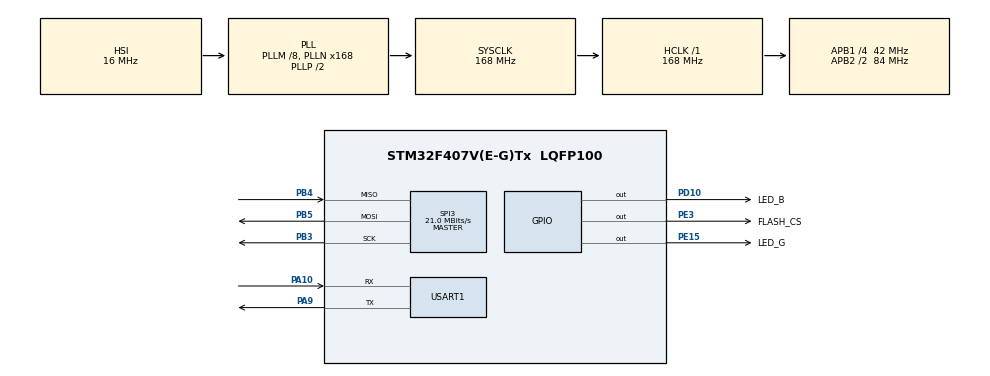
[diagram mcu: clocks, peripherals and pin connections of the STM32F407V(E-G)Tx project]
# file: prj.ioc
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Dma.Request0=SPI3_TX
Dma.Request1=SPI3_RX
Dma.SPI3_RX.1.Direction=DMA_PERIPH_TO_MEMORY
Dma.SPI3_RX.1.FIFOMode=DMA_FIFOMODE_DISABLE
Dma.SPI3_RX.1.Instance=DMA1_Stream0
Dma.SPI3_RX.1.MemDataAlignment=DMA_MDATAALIGN_BYTE
Dma.SPI3_RX.1.MemInc=DMA_MINC_ENABLE
Dma.SPI3_RX.1.Mode=DMA_NORMAL
Dma.SPI3_RX.1.PeriphDataAlignment=DMA_PDATAALIGN_BYTE
Dma.SPI3_RX.1.PeriphInc=DMA_PINC_DISABLE
Dma.SPI3_RX.1.Priority=DMA_PRIORITY_HIGH
Dma.SPI3_TX.0.Direction=DMA_MEMORY_TO_PERIPH
Dma.SPI3_TX.0.FIFOMode=DMA_FIFOMODE_DISABLE
Dma.SPI3_TX.0.Instance=DMA1_Stream5
Dma.SPI3_TX.0.MemDataAlignment=DMA_MDATAALIGN_BYTE
Dma.SPI3_TX.0.MemInc=DMA_MINC_ENABLE
Dma.SPI3_TX.0.Mode=DMA_NORMAL
Dma.SPI3_TX.0.PeriphDataAlignment=DMA_PDATAALIGN_BYTE
Dma.SPI3_TX.0.PeriphInc=DMA_PINC_DISABLE
Dma.SPI3_TX.0.Priority=DMA_PRIORITY_HIGH
FREERTOS.Tasks01=defaultTask,24,128,StartDefaultTask,Default,NULL,Dynamic,NULL,NULL;flashTask,24,512,FlashTask,Default,NULL,Static,flashTaskBuffer,flashTaskControlBlock
FREERTOS.configENABLE_FPU=1
Mcu.Family=STM32F4
Mcu.Name=STM32F407V(E-G)Tx
Mcu.Package=LQFP100
NVIC.DMA1_Stream0_IRQn=true\:0\:0\:false\:false\:true\:false\:false\:true\:true
NVIC.DMA1_Stream5_IRQn=true\:5\:0\:false\:false\:true\:true\:false\:true\:true
NVIC.PriorityGroup=NVIC_PRIORITYGROUP_4
NVIC.TIM1_UP_TIM10_IRQn=true\:15\:0\:false\:false\:true\:false\:false\:true\:true
NVIC.TimeBase=TIM1_UP_TIM10_IRQn
NVIC.TimeBaseIP=TIM1
NVIC.USART1_IRQn=true\:5\:0\:false\:false\:true\:true\:true\:true\:true
PA10.Mode=Asynchronous
PA10.Signal=USART1_RX
PA13.Mode=Serial_Wire
PA13.Signal=SYS_JTMS-SWDIO
PA14.Mode=Serial_Wire
PA14.Signal=SYS_JTCK-SWCLK
PA9.Mode=Asynchronous
PA9.Signal=USART1_TX
PB3.Mode=Full_Duplex_Master
PB3.Signal=SPI3_SCK
PB4.Mode=Full_Duplex_Master
PB4.Signal=SPI3_MISO
PB5.Mode=Full_Duplex_Master
PB5.Signal=SPI3_MOSI
PC14-OSC32_IN.Mode=LSE-External-Oscillator
PC14-OSC32_IN.Signal=RCC_OSC32_IN
PC15-OSC32_OUT.Mode=LSE-External-Oscillator
PC15-OSC32_OUT.Signal=RCC_OSC32_OUT
PD10.GPIO_Label=LED_B
PD10.Signal=GPIO_Output
PE15.GPIO_Label=LED_G
PE15.Signal=GPIO_Output
PE3.GPIO_Label=FLASH_CS
PE3.GPIO_PuPd=GPIO_PULLUP
PE3.GPIO_Speed=GPIO_SPEED_FREQ_VERY_HIGH
PE3.PinState=GPIO_PIN_SET
PE3.Signal=GPIO_Output
PH0-OSC_IN.Mode=HSE-External-Oscillator
PH0-OSC_IN.Signal=RCC_OSC_IN
PH1-OSC_OUT.Mode=HSE-External-Oscillator
PH1-OSC_OUT.Signal=RCC_OSC_OUT
ProjectManager.HeapSize=0x200
ProjectManager.StackSize=0x400
ProjectManager.TargetToolchain=MDK-ARM V5.32
RCC.48MHZClocksFreq_Value=84000000
RCC.AHBFreq_Value=168000000
RCC.APB1CLKDivider=RCC_HCLK_DIV4
RCC.APB1Freq_Value=42000000
RCC.APB1TimFreq_Value=84000000
RCC.APB2CLKDivider=RCC_HCLK_DIV2
RCC.APB2Freq_Value=84000000
RCC.APB2TimFreq_Value=168000000
RCC.CortexFreq_Value=168000000
RCC.HCLKFreq_Value=168000000
RCC.HSE_VALUE=25000000
RCC.HSI_VALUE=16000000
RCC.PLLM=8
RCC.PLLN=168
RCC.SYSCLKFreq_VALUE=168000000
RCC.SYSCLKSource=RCC_SYSCLKSOURCE_PLLCLK
RCC.VCOOutputFreq_Value=336000000
SPI3.CalculateBaudRate=21.0 MBits/s
SPI3.Direction=SPI_DIRECTION_2LINES
SPI3.Mode=SPI_MODE_MASTER
SPI3.VirtualType=VM_MASTER
USART1.VirtualMode=VM_ASYNC
VP_FREERTOS_VS_CMSIS_V2.Mode=CMSIS_V2
VP_SYS_VS_tim1.Mode=TIM1
board=custom

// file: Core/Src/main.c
/* USER CODE BEGIN Header */
/**
  ******************************************************************************
  * @file           : main.c
  * @brief          : Main program body
  ******************************************************************************
  * @attention
  *
  * Copyright (c) 2025 STMicroelectronics.
  * All rights reserved.
  *
  * This software is licensed under terms that can be found in the LICENSE file
  * in the root directory of this software component.
  * If no LICENSE file comes with this software, it is provided AS-IS.
  *
  ******************************************************************************
  */
/* USER CODE END Header */
#include "main.h"
#include "cmsis_os.h"
#include "dma.h"
#include "spi.h"
#include "usart.h"
#include "gpio.h"

void SystemClock_Config(void);
void MX_FREERTOS_Init(void);

int main(void)
{

  /* MCU Configuration--------------------------------------------------------*/

  /* Reset of all peripherals, Initializes the Flash interface and the Systick. */
  HAL_Init();

  /* Configure the system clock */
  SystemClock_Config();

  /* Initialize all configured peripherals */
  MX_GPIO_Init();
  MX_DMA_Init();
  MX_SPI3_Init();
  MX_USART1_UART_Init();

  /* Init scheduler */
  osKernelInitialize();

  /* Call init function for freertos objects (in cmsis_os2.c) */
  MX_FREERTOS_Init();

  /* Start scheduler */
  osKernelStart();

  /* We should never get here as control is now taken by the scheduler */

  /* Infinite loop */
  while (1)
  {

  }
}

void SystemClock_Config(void)
{
  RCC_OscInitTypeDef RCC_OscInitStruct = {0};
  RCC_ClkInitTypeDef RCC_ClkInitStruct = {0};

  /** Configure the main internal regulator output voltage
  */
  __HAL_RCC_PWR_CLK_ENABLE();
  __HAL_PWR_VOLTAGESCALING_CONFIG(PWR_REGULATOR_VOLTAGE_SCALE1);

  /** Initializes the RCC Oscillators according to the specified parameters
  * in the RCC_OscInitTypeDef structure.
  */
  RCC_OscInitStruct.OscillatorType = RCC_OSCILLATORTYPE_HSI;
  RCC_OscInitStruct.HSIState = RCC_HSI_ON;
  RCC_OscInitStruct.HSICalibrationValue = RCC_HSICALIBRATION_DEFAULT;
  RCC_OscInitStruct.PLL.PLLState = RCC_PLL_ON;
  RCC_OscInitStruct.PLL.PLLSource = RCC_PLLSOURCE_HSI;
  RCC_OscInitStruct.PLL.PLLM = 8;
  RCC_OscInitStruct.PLL.PLLN = 168;
  RCC_OscInitStruct.PLL.PLLP = RCC_PLLP_DIV2;
  RCC_OscInitStruct.PLL.PLLQ = 4;
  if (HAL_RCC_OscConfig(&RCC_OscInitStruct) != HAL_OK)
  {
    Error_Handler();
  }

  /** Initializes the CPU, AHB and APB buses clocks
  */
  RCC_ClkInitStruct.ClockType = RCC_CLOCKTYPE_HCLK|RCC_CLOCKTYPE_SYSCLK
                              |RCC_CLOCKTYPE_PCLK1|RCC_CLOCKTYPE_PCLK2;
  RCC_ClkInitStruct.SYSCLKSource = RCC_SYSCLKSOURCE_PLLCLK;
  RCC_ClkInitStruct.AHBCLKDivider = RCC_SYSCLK_DIV1;
  RCC_ClkInitStruct.APB1CLKDivider = RCC_HCLK_DIV4;
  RCC_ClkInitStruct.APB2CLKDivider = RCC_HCLK_DIV2;

  if (HAL_RCC_ClockConfig(&RCC_ClkInitStruct, FLASH_LATENCY_5) != HAL_OK)
  {
    Error_Handler();
  }
}

void HAL_TIM_PeriodElapsedCallback(TIM_HandleTypeDef *htim)
{
  if (htim->Instance == TIM1)
  {
    HAL_IncTick();
  }
}

void Error_Handler(void)
{
  __disable_irq();
  while (1)
  {
  }
}

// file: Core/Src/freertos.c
/* USER CODE BEGIN Header */
/**
  ******************************************************************************
  * File Name          : freertos.c
  * Description        : Code for freertos applications
  ******************************************************************************
  * @attention
  *
  * Copyright (c) 2025 STMicroelectronics.
  * All rights reserved.
  *
  * This software is licensed under terms that can be found in the LICENSE file
  * in the root directory of this software component.
  * If no LICENSE file comes with this software, it is provided AS-IS.
  *
  ******************************************************************************
  */
/* USER CODE END Header */

#include "FreeRTOS.h"
#include "task.h"
#include "main.h"
#include "cmsis_os.h"

/* USER CODE BEGIN Includes */
#include "Dev_Flash.h"
#include "usart.h"
/* USER CODE END Includes */

typedef StaticTask_t osStaticThreadDef_t;

/* Definitions for defaultTask */
osThreadId_t defaultTaskHandle;
const osThreadAttr_t defaultTask_attributes = {
  .name = "defaultTask",
  .stack_size = 128 * 4,
  .priority = (osPriority_t) osPriorityNormal,
};
/* Definitions for flashTask */
osThreadId_t flashTaskHandle;
uint32_t flashTaskBuffer[ 512 ];
osStaticThreadDef_t flashTaskControlBlock;
const osThreadAttr_t flashTask_attributes = {
  .name = "flashTask",
  .cb_mem = &flashTaskControlBlock,
  .cb_size = sizeof(flashTaskControlBlock),
  .stack_mem = &flashTaskBuffer[0],
  .stack_size = sizeof(flashTaskBuffer),
  .priority = (osPriority_t) osPriorityNormal,
};

void StartDefaultTask(void *argument);
void FlashTask(void *argument);

void MX_FREERTOS_Init(void); /* (MISRA C 2004 rule 8.1) */

void MX_FREERTOS_Init(void) {

  /* Create the thread(s) */
  /* creation of defaultTask */
  defaultTaskHandle = osThreadNew(StartDefaultTask, NULL, &defaultTask_attributes);

  /* creation of flashTask */
  flashTaskHandle = osThreadNew(FlashTask, NULL, &flashTask_attributes);

}

void StartDefaultTask(void *argument)
{
  /* USER CODE BEGIN StartDefaultTask */
  /* Infinite loop */
  for(;;)
  {
    HAL_GPIO_TogglePin(LED_G_GPIO_Port, LED_G_Pin);
    HAL_GPIO_TogglePin(LED_B_GPIO_Port, LED_B_Pin);
    osDelay(200);
  }
  /* USER CODE END StartDefaultTask */
}

void FlashTask(void *argument)
{
  /* USER CODE BEGIN FlashTask */
  W25Q32_SectorErase(0x000000);
  W25Q32_PageProgram(0x000000, (const uint8_t *)"Hello, W32q76 Flash!", 20);
  /* Infinite loop */
  for(;;)
  {
    uint8_t readBuffer[20];
    W25Q32_ReadData(0x000000, readBuffer, 20);
    HAL_UART_Transmit(&huart1, readBuffer, 20, HAL_MAX_DELAY);
    osDelay(500);
  }
  /* USER CODE END FlashTask */
}
